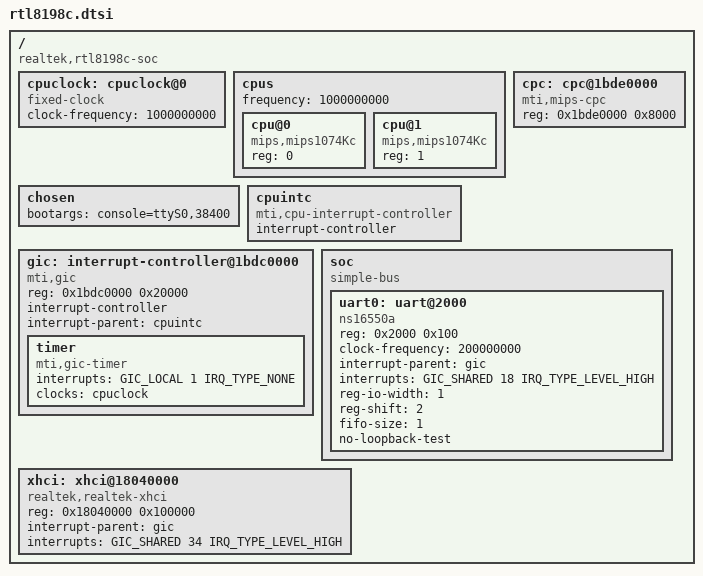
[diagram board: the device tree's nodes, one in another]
// SPDX-License-Identifier: GPL-2.0-or-later OR MIT

#include <dt-bindings/interrupt-controller/mips-gic.h>


/dts-v1/;

/ {
	#address-cells = <1>;
	#size-cells = <1>;

	compatible = "realtek,rtl8198c-soc";

	cpuclock: cpuclock@0 {
		#clock-cells = <0>;
		compatible = "fixed-clock";
		clock-frequency = <1000000000>;
	};

	cpus {
		#address-cells = <1>;
		#size-cells = <0>;
		frequency = <1000000000>;

		cpu@0 {
			compatible = "mips,mips1074Kc";
			reg = <0>;
		};

		cpu@1 {
			compatible = "mips,mips1074Kc";
			reg = <1>;
		};
	};

	chosen {
		bootargs = "console=ttyS0,38400";
	};

	cpc: cpc@1bde0000 {
		compatible = "mti,mips-cpc";
		reg = <0x1bde0000 0x8000>;
	};

	cpuintc: cpuintc {
		compatible = "mti,cpu-interrupt-controller";
		#address-cells = <0>;
		#interrupt-cells = <1>;
		interrupt-controller;
	};

	gic: interrupt-controller@1bdc0000 {
		compatible = "mti,gic";
		reg = <0x1bdc0000 0x20000>;

		interrupt-controller;
		#interrupt-cells = <3>;

		/*
		 * Declare the interrupt-parent even though the mti,gic
		 * binding doesn't require it, such that the kernel can
		 * figure out that cpu_intc is the root interrupt
		 * controller & should be probed first.
		 */
		interrupt-parent = <&cpuintc>;

		timer {
			compatible = "mti,gic-timer";
			interrupts = <GIC_LOCAL 1 IRQ_TYPE_NONE>;
			clocks = <&cpuclock>;
		};
	};

	soc: soc {
		compatible = "simple-bus";
		#address-cells = <1>;
		#size-cells = <1>;
		ranges = <0x0 0x18000000 0x10000>;

		uart0: uart@2000 {
			compatible = "ns16550a";
			reg = <0x2000 0x100>;

			clock-frequency = <200000000>;

			interrupt-parent = <&gic>;
			#interrupt-cells = <3>;
			interrupts = <GIC_SHARED 18 IRQ_TYPE_LEVEL_HIGH>;

			reg-io-width = <1>;
			reg-shift = <2>;
			fifo-size = <1>;
			no-loopback-test;
		};

	};

	xhci: xhci@18040000 {
		compatible = "realtek,realtek-xhci";
		reg = <0x18040000 0x100000>;
		interrupt-parent = <&gic>;
		interrupts = <GIC_SHARED 34 IRQ_TYPE_LEVEL_HIGH>;
	};
};
